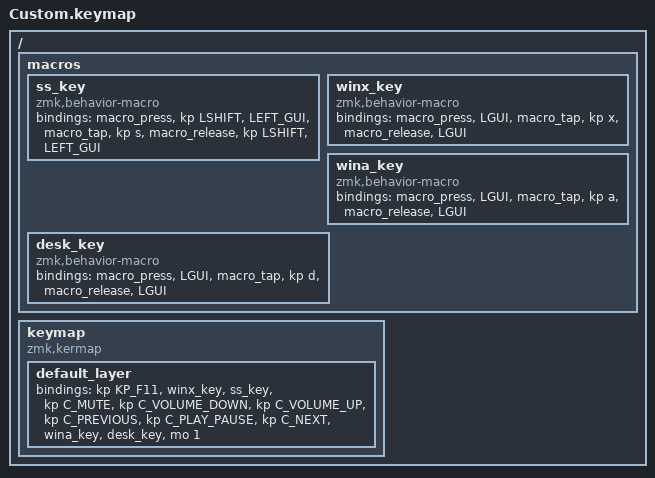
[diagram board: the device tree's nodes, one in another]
#include <behavior.dtsi>
#include <dt-bindings/zmk/keys.h>
#include <dt-bindings/zmk/bt.h>
#include <dt-bindings/zmk/outputs.h>

/{
    macros {
        ss_key: ss_key {
            compatible = "zmk,behavior-macro";
            #binding-cells = <0>;
            bindings
                = <&macro_press &kp LSHIFT &LEFT_GUI>
                , <&macro_tap &kp s>
                , <&macro_release &kp LSHIFT &LEFT_GUI>
                ;
        };
        winx_key: winx_key {
            compatible = "zmk,behavior-macro";
            #binding-cells = <0>;
            bindings
                = <&macro_press &LGUI>
                , <&macro_tap &kp x>
                , <&macro_release &LGUI>
                ;
        };
        wina_key: wina_key {
            compatible = "zmk,behavior-macro";
            #binding-cells = <0>;
            bindings
                = <&macro_press &LGUI>
                , <&macro_tap &kp a>
                , <&macro_release &LGUI>
                ;
        };
        desk_key: desk_key {
            compatible = "zmk,behavior-macro";
            #binding-cells = <0>;
            bindings
                = <&macro_press &LGUI>
                , <&macro_tap &kp d>
                , <&macro_release &LGUI>
                ;
        };
    };

    keymap{
        compatible = "zmk,kermap";

        default_layer {
            bindings = <
                &kp KP_F11      &winx_key           &ss_key
                &kp C_MUTE      &kp C_VOLUME_DOWN   &kp C_VOLUME_UP
                &kp C_PREVIOUS  &kp C_PLAY_PAUSE    &kp C_NEXT
                &wina_key       &desk_key           &mo 1
            >;
        };
    };
};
